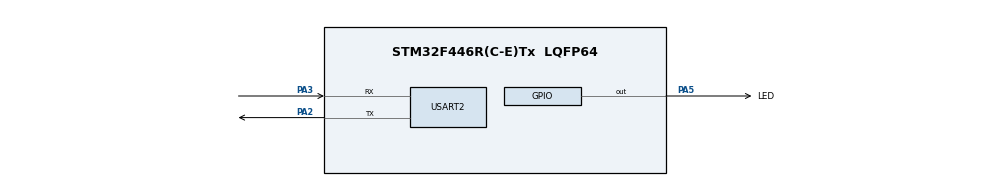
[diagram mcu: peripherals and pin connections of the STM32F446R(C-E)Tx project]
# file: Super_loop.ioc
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Mcu.Family=STM32F4
Mcu.Name=STM32F446R(C-E)Tx
Mcu.Package=LQFP64
NVIC.PriorityGroup=NVIC_PRIORITYGROUP_4
NVIC.TIM3_IRQn=true\:0\:0\:false\:false\:true\:true\:true\:true
PA13.Mode=Serial_Wire
PA13.Signal=SYS_JTMS-SWDIO
PA14.Mode=Serial_Wire
PA14.Signal=SYS_JTCK-SWCLK
PA2.Mode=Asynchronous
PA2.Signal=USART2_TX
PA3.Mode=Asynchronous
PA3.Signal=USART2_RX
PA5.GPIO_Label=LED
PA5.Signal=GPIO_Output
PC14-OSC32_IN.Mode=LSE-External-Oscillator
PC14-OSC32_IN.Signal=RCC_OSC32_IN
PC15-OSC32_OUT.Mode=LSE-External-Oscillator
PC15-OSC32_OUT.Signal=RCC_OSC32_OUT
PH0-OSC_IN.Mode=HSE-External-Oscillator
PH0-OSC_IN.Signal=RCC_OSC_IN
PH1-OSC_OUT.Mode=HSE-External-Oscillator
PH1-OSC_OUT.Signal=RCC_OSC_OUT
ProjectManager.HeapSize=0x200
ProjectManager.StackSize=0x400
ProjectManager.TargetToolchain=STM32CubeIDE
RCC.CortexFreq_Value=16000000
RCC.USBFreq_Value=96000000
RCC.VCOOutputFreq_Value=192000000
TIM3.Period=9999
TIM3.Prescaler=8399
USART2.VirtualMode=VM_ASYNC
VP_TIM3_VS_ClockSourceINT.Mode=Internal
board=custom

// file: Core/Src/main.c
/* USER CODE BEGIN Header */
/**
  ******************************************************************************
  * @file           : main.c
  * @brief          : Main program body
  ******************************************************************************
  * @attention
  *
  * Copyright (c) 2025 STMicroelectronics.
  * All rights reserved.
  *
  * This software is licensed under terms that can be found in the LICENSE file
  * in the root directory of this software component.
  * If no LICENSE file comes with this software, it is provided AS-IS.
  *
  ******************************************************************************
  */
/* USER CODE END Header */
#include "main.h"

/* USER CODE BEGIN Includes */
#include <stdio.h>
/* USER CODE END Includes */

TIM_HandleTypeDef htim3;

UART_HandleTypeDef huart2;

/* USER CODE BEGIN PV */
volatile uint8_t flag1 = 0;
volatile uint8_t flag2 = 0;
volatile uint8_t flag3 = 0;
/* USER CODE END PV */

void SystemClock_Config(void);
static void MX_GPIO_Init(void);
static void MX_USART2_UART_Init(void);
static void MX_TIM3_Init(void);

int main(void)
{

  /* MCU Configuration--------------------------------------------------------*/

  /* Reset of all peripherals, Initializes the Flash interface and the Systick. */
  HAL_Init();

  /* Configure the system clock */
  SystemClock_Config();

  /* Initialize all configured peripherals */
  MX_GPIO_Init();
  MX_USART2_UART_Init();
  MX_TIM3_Init();
  /* USER CODE BEGIN 2 */
  HAL_TIM_Base_Start_IT(&htim3);
  char msg[50];

  printf("UART Initialized. Starting Super Loop...\r\n");

  /* USER CODE END 2 */

  /* Infinite loop */
  while (1)
  {

    /* USER CODE BEGIN 3 */
	if (flag1)
	{
	HAL_GPIO_TogglePin(GPIOA, GPIO_PIN_5); // Toggle LED
	sprintf(msg, "Action for Flag1 (LED toggle)\r\n");
	HAL_UART_Transmit(&huart2, (uint8_t *)msg, strlen(msg), HAL_MAX_DELAY);
	flag1 = 0;
	}

	if (flag2)
	{
	sprintf(msg, "Action for Flag2\r\n");
	HAL_UART_Transmit(&huart2, (uint8_t *)msg, strlen(msg), HAL_MAX_DELAY);
	flag2 = 0;
	}

	if (flag3)
	{
	sprintf(msg, "Action for Flag3\r\n");
	HAL_UART_Transmit(&huart2, (uint8_t *)msg, strlen(msg), HAL_MAX_DELAY);
	flag3 = 0;
	}
  }
  /* USER CODE END 3 */
}
void HAL_TIM_PeriodElapsedCallback(TIM_HandleTypeDef *htim)
{
  static int count = 0;
  if (htim->Instance == TIM3)
  {
    count++;
    flag1 = 1;                    // Every 1s
    if (count % 3 == 0) flag2 = 1; // Every 3s
    if (count % 5 == 0) flag3 = 1; // Every 5s
  }
}
void SystemClock_Config(void)
{
  RCC_OscInitTypeDef RCC_OscInitStruct = {0};
  RCC_ClkInitTypeDef RCC_ClkInitStruct = {0};

  /** Configure the main internal regulator output voltage
  */
  __HAL_RCC_PWR_CLK_ENABLE();
  __HAL_PWR_VOLTAGESCALING_CONFIG(PWR_REGULATOR_VOLTAGE_SCALE3);

  /** Initializes the RCC Oscillators according to the specified parameters
  * in the RCC_OscInitTypeDef structure.
  */
  RCC_OscInitStruct.OscillatorType = RCC_OSCILLATORTYPE_HSI;
  RCC_OscInitStruct.HSIState = RCC_HSI_ON;
  RCC_OscInitStruct.HSICalibrationValue = RCC_HSICALIBRATION_DEFAULT;
  RCC_OscInitStruct.PLL.PLLState = RCC_PLL_NONE;
  if (HAL_RCC_OscConfig(&RCC_OscInitStruct) != HAL_OK)
  {
    Error_Handler();
  }

  /** Initializes the CPU, AHB and APB buses clocks
  */
  RCC_ClkInitStruct.ClockType = RCC_CLOCKTYPE_HCLK|RCC_CLOCKTYPE_SYSCLK
                              |RCC_CLOCKTYPE_PCLK1|RCC_CLOCKTYPE_PCLK2;
  RCC_ClkInitStruct.SYSCLKSource = RCC_SYSCLKSOURCE_HSI;
  RCC_ClkInitStruct.AHBCLKDivider = RCC_SYSCLK_DIV1;
  RCC_ClkInitStruct.APB1CLKDivider = RCC_HCLK_DIV1;
  RCC_ClkInitStruct.APB2CLKDivider = RCC_HCLK_DIV1;

  if (HAL_RCC_ClockConfig(&RCC_ClkInitStruct, FLASH_LATENCY_0) != HAL_OK)
  {
    Error_Handler();
  }
}

static void MX_TIM3_Init(void)
{

  TIM_ClockConfigTypeDef sClockSourceConfig = {0};
  TIM_MasterConfigTypeDef sMasterConfig = {0};

  htim3.Instance = TIM3;
  htim3.Init.Prescaler = 8399;
  htim3.Init.CounterMode = TIM_COUNTERMODE_UP;
  htim3.Init.Period = 9999;
  htim3.Init.ClockDivision = TIM_CLOCKDIVISION_DIV1;
  htim3.Init.AutoReloadPreload = TIM_AUTORELOAD_PRELOAD_DISABLE;
  if (HAL_TIM_Base_Init(&htim3) != HAL_OK)
  {
    Error_Handler();
  }
  sClockSourceConfig.ClockSource = TIM_CLOCKSOURCE_INTERNAL;
  if (HAL_TIM_ConfigClockSource(&htim3, &sClockSourceConfig) != HAL_OK)
  {
    Error_Handler();
  }
  sMasterConfig.MasterOutputTrigger = TIM_TRGO_RESET;
  sMasterConfig.MasterSlaveMode = TIM_MASTERSLAVEMODE_DISABLE;
  if (HAL_TIMEx_MasterConfigSynchronization(&htim3, &sMasterConfig) != HAL_OK)
  {
    Error_Handler();
  }

}

static void MX_USART2_UART_Init(void)
{

  huart2.Instance = USART2;
  huart2.Init.BaudRate = 115200;
  huart2.Init.WordLength = UART_WORDLENGTH_8B;
  huart2.Init.StopBits = UART_STOPBITS_1;
  huart2.Init.Parity = UART_PARITY_NONE;
  huart2.Init.Mode = UART_MODE_TX_RX;
  huart2.Init.HwFlowCtl = UART_HWCONTROL_NONE;
  huart2.Init.OverSampling = UART_OVERSAMPLING_16;
  if (HAL_UART_Init(&huart2) != HAL_OK)
  {
    Error_Handler();
  }

}

static void MX_GPIO_Init(void)
{
  GPIO_InitTypeDef GPIO_InitStruct = {0};

  /* GPIO Ports Clock Enable */
  __HAL_RCC_GPIOC_CLK_ENABLE();
  __HAL_RCC_GPIOH_CLK_ENABLE();
  __HAL_RCC_GPIOA_CLK_ENABLE();

  /*Configure GPIO pin Output Level */
  HAL_GPIO_WritePin(LED_GPIO_Port, LED_Pin, GPIO_PIN_RESET);

  /*Configure GPIO pin : LED_Pin */
  GPIO_InitStruct.Pin = LED_Pin;
  GPIO_InitStruct.Mode = GPIO_MODE_OUTPUT_PP;
  GPIO_InitStruct.Pull = GPIO_NOPULL;
  GPIO_InitStruct.Speed = GPIO_SPEED_FREQ_LOW;
  HAL_GPIO_Init(LED_GPIO_Port, &GPIO_InitStruct);

}

void Error_Handler(void)
{
  __disable_irq();
  while (1)
  {
  }
}
